# MKM34ZA5 register map
Vendor: Freescale Semiconductor, Inc.; File version: 1.6
CPU: CM0PLUS r0p0, little endian, no MPU, no FPU, 0x2 interrupt priority bits, 0x0 interrupts
Registers are 32-bit, read-write, reset 0x0 unless marked. A register's access mark holds for its fields unless they carry their own. Offsets are from the block's base; [hi:lo] are bit positions; {n}, {i} and the like mark numbered series; 'fields as' and 'values as' point back to an identical list.

## MPU — Memory protection unit
Base 0x4000A000; register names take the prefix MPU_
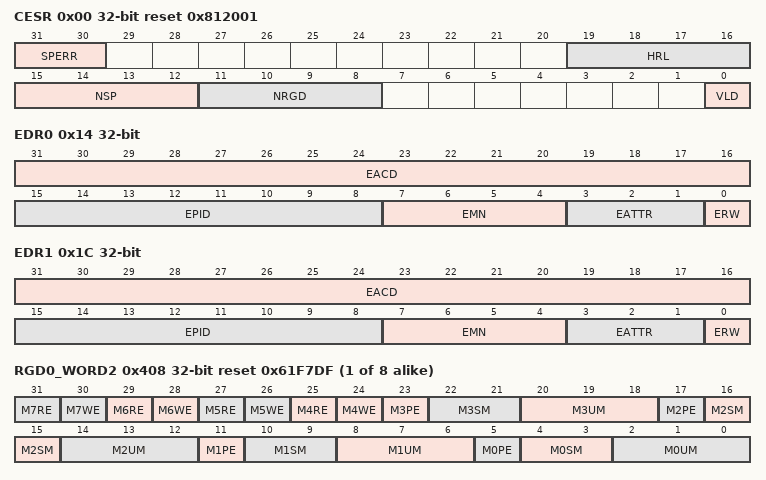
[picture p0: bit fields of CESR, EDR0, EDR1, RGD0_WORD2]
0x00 CESR reset 0x812001 — Control/Error Status Register
  [31:30] SPERR — Slave Port n Error
    0=No error has occurred for slave port n; 1=An error has occurred for slave port n
  [19:16] HRL ro — Hardware Revision Level
  [15:12] NSP ro — Number Of Slave Ports
  [11:8] NRGD ro — Number Of Region Descriptors
    0=8 region descriptors; 1=12 region descriptors; 2=16 region descriptors
  [0] VLD — Valid
    0=MPU is disabled. All accesses from all bus masters are allowed.; 1=MPU is enabled
0x10 EAR0 ro — Error Address Register, slave port n
  [31:0] EADDR — Error Address
0x14 EDR0 ro — Error Detail Register, slave port n
  [31:16] EACD — Error Access Control Detail
  [15:8] EPID — Error Process Identification
  [7:4] EMN — Error Master Number
  [3:1] EATTR — Error Attributes
    0=User mode, instruction access; 1=User mode, data access; 2=Supervisor mode, instruction access; 3=Supervisor mode, data access
  [0] ERW — Error Read/Write
    0=Read; 1=Write
0x18 EAR1 ro — Error Address Register, slave port n
  [31:0] EADDR — Error Address
0x1C EDR1 ro — Error Detail Register, slave port n
  fields as EDR0
{0x400+0x10*i} RGD{i}_WORD0 (i=0..7) — Region Descriptor n, Word 0
  [31:5] SRTADDR — Start Address
{0x404+0x10*i} RGD{i}_WORD1 reset 0xFFFFFFFF (i=0..7) — Region Descriptor n, Word 1
  [31:5] ENDADDR — End Address
{0x408+0x10*i} RGD{i}_WORD2 reset 0x61F7DF (i=0..7) — Region Descriptor n, Word 2
  [2n+17] M{n}RE (n=4..7) — Bus Master {n} Read Enable
    0=Bus master {n} reads terminate with an access error and the read is not performed; 1=Bus master {n} reads allowed
  [2n+16] M{n}WE (n=4..7) — Bus Master {n} Write Enable
    0=Bus master {n} writes terminate with an access error and the write is not performed; 1=Bus master {n} writes allowed
  [23] M3PE — Bus Master 3 Process Identifier Enable
    0=Do not include the process identifier in the evaluation; 1=Include the process identifier and mask (RGDn_WORD3) in the region hit evaluation
  [22:21] M3SM — Bus Master 3 Supervisor Mode Access Control
    0=r/w/x; read, write and execute allowed; 1=r/x; read and execute allowed, but no write; 2=r/w; read and write allowed, but no execute; 3=Same as User mode defined in M3UM
  [20:18] M3UM — Bus Master 3 User Mode Access Control
    0=An attempted access of that mode may be terminated with an access error (if not allowed by another descriptor) and the access not performed; 1=Allows the given access type to occur
  [17] M2PE — Bus Master 2 Process Identifier Enable
  [16:15] M2SM — Bus Master 2 Supervisor Mode Access Control
  [14:12] M2UM — Bus Master 2 User Mode Access control
  [11] M1PE — Bus Master 1 Process Identifier enable
  [10:9] M1SM — Bus Master 1 Supervisor Mode Access Control
  [8:6] M1UM — Bus Master 1 User Mode Access Control
  [5] M0PE — Bus Master 0 Process Identifier enable
  [4:3] M0SM — Bus Master 0 Supervisor Mode Access Control
  [2:0] M0UM — Bus Master 0 User Mode Access Control
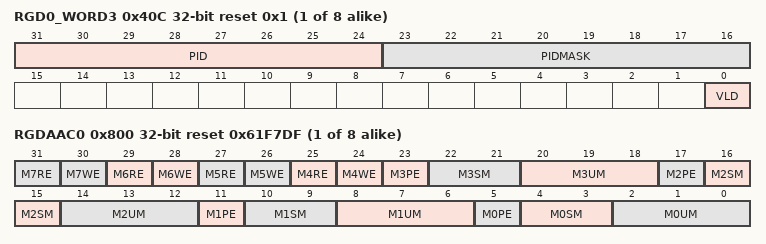
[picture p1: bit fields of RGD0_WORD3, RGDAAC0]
{0x40C+0x10*i} RGD{i}_WORD3 reset 0x1 (i=0..7) — Region Descriptor n, Word 3
  [31:24] PID — Process Identifier
  [23:16] PIDMASK — Process Identifier Mask
  [0] VLD — Valid
    0=Region descriptor is invalid; 1=Region descriptor is valid
{0x800+4i} RGDAAC{i} reset 0x61F7DF (i=0..7) — Region Descriptor Alternate Access Control n
  [2n+17] M{n}RE (n=4..7) — Bus Master {n} Read Enable
    values as RGD0_WORD2.M4RE
  [2n+16] M{n}WE (n=4..7) — Bus Master {n} Write Enable
    values as RGD0_WORD2.M4WE
  [23] M3PE — Bus Master 3 Process Identifier Enable
    0=Do not include the process identifier in the evaluation; 1=Include the process identifier and mask (RGDn.RGDAAC) in the region hit evaluation
  [22:21] M3SM — Bus Master 3 Supervisor Mode Access Control
    values as RGD0_WORD2.M3SM
  [20:18] M3UM — Bus Master 3 User Mode Access Control
    values as RGD0_WORD2.M3UM
  [17] M2PE — Bus Master 2 Process Identifier Enable
  [16:15] M2SM — Bus Master 2 Supervisor Mode Access Control
  [14:12] M2UM — Bus Master 2 User Mode Access Control
  [11] M1PE — Bus Master 1 Process Identifier Enable
  [10:9] M1SM — Bus Master 1 Supervisor Mode Access Control
  [8:6] M1UM — Bus Master 1 User Mode Access Control
  [5] M0PE — Bus Master 0 Process Identifier Enable
  [4:3] M0SM — Bus Master 0 Supervisor Mode Access Control
  [2:0] M0UM — Bus Master 0 User Mode Access Control
